# DMIC_DSP register map
Vendor: Texas Instruments
Peripheral module from a debugger description file (folder omap4460).
Registers are 32-bit, read-only, reset 0x0 unless marked. A register's access mark holds for its fields unless they carry their own. Offsets are as the file gives them; lines under a group give offsets from that group; [hi:lo] are bit positions; {n}, {i} and the like mark numbered series; 'fields as' and 'values as' point back to an identical list; <NAME> marks a mode.

## DMIC_DSP
0x00 DMIC_REVISION reset not defined — IP Revision Identifier (X.Y.R) used by software to track features, bugs, and compatibility
  [31:0] REVISION — IP revision
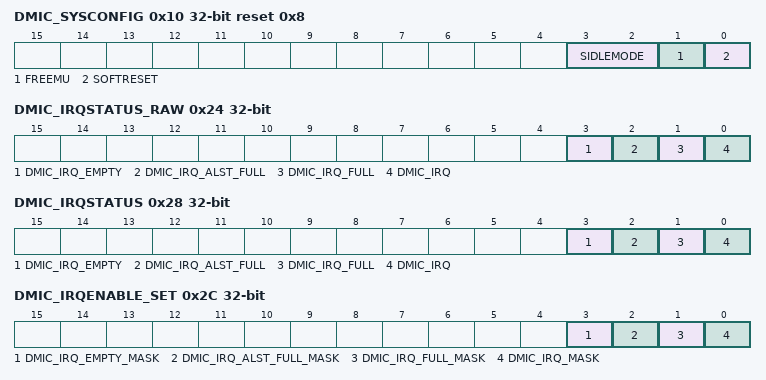
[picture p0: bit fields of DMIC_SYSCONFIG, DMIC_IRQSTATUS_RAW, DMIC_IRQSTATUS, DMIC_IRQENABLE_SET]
0x10 DMIC_SYSCONFIG access per field reset 0x8 — This register allows controlling various parameters of the DMIC interface.
  [3:2] SIDLEMODE rw — Configuration of the local target state management (idlereq/idleack control)
    0=Force-idle. IDLE request is acknowledged unconditionally and immediately.; 1=No-idle. IDLE request is never acknowledged.; 2=Smart-idle. The acknowledgment to an IDLE request is given based on the internal activity.; 3=Smart-idle wakeup capable mode
  [1] FREEMU rw — Sensitivity to emulation (debug) suspend input signal
    0=IP module is sensitive to emulation suspend; 1=IP module is not sensitive to emulation suspend
  [0] SOFTRESET rw — Module software reset. The bit is automatically reset by the hardware. It has same effect as the main hardware reset.
    0=SOFTRESET_0_w (No action); 0=SOFTRESET_0_r (Reset done, no pending action); 1=SOFTRESET_1_r (Reset (software or other) ongoing); 1=SOFTRESET_1_w (Initiate software reset.)
0x24 DMIC_IRQSTATUS_RAW access not given — Component (that is, main) interrupt request status. Check the corresponding secondary status register. Raw status is set even if event is not enabled. Write 1 to set the (raw) status, mostly for debug.
  [3] DMIC_IRQ_EMPTY rw
    0=DMIC_IRQ_EMPTY_0_r (No event pending); 0=DMIC_IRQ_EMPTY_0_w (No action); 1=DMIC_IRQ_EMPTY_1_w (Set); 1=DMIC_IRQ_EMPTY_1_r (IRQ event pending)
  [2] DMIC_IRQ_ALST_FULL — (access RW W1toSet)
    0=DMIC_IRQ_ALST_FULL_0_r (No event pending); 0=DMIC_IRQ_ALST_FULL_0_w (No action); 1=DMIC_IRQ_ALST_FULL_1_w (Set); 1=DMIC_IRQ_ALST_FULL_1_r (IRQ event pending)
  [1] DMIC_IRQ_FULL — (access RW W1toSet)
    0=DMIC_IRQ_FULL_0_r (No event pending); 0=DMIC_IRQ_FULL_0_w (No action); 1=DMIC_IRQ_FULL_1_w (Set); 1=DMIC_IRQ_FULL_1_r (IRQ event pending)
  [0] DMIC_IRQ — (access RW W1toSet)
    0=DMIC_IRQ_0_r (No event pending); 0=DMIC_IRQ_0_w (No action); 1=DMIC_IRQ_1_w (Set); 1=DMIC_IRQ_1_r (IRQ event pending)
0x28 DMIC_IRQSTATUS access not given — Component (that is, main) interrupt request status. Check the corresponding secondary status register. Enabled status is not set unless event is enabled. Write 1 to clear the status after interrupt has been serviced (raw status gets cleared, that is, even if not enabled).
  [3] DMIC_IRQ_EMPTY rw
    0=DMIC_IRQ_EMPTY_0_r (No event pending); 0=DMIC_IRQ_EMPTY_0_w (No action); 1=DMIC_IRQ_EMPTY_1_w (Clear pending event, if any); 1=DMIC_IRQ_EMPTY_1_r (IRQ event pending)
  [2] DMIC_IRQ_ALST_FULL — This interrupt status is set when only one FIFO space is still available. (access RW W1toClr)
    0=DMIC_IRQ_ALST_FULL_0_r (No event pending); 0=DMIC_IRQ_ALST_FULL_0_w (No action); 1=DMIC_IRQ_ALST_FULL_1_w (Clear pending event, if any); 1=DMIC_IRQ_ALST_FULL_1_r (IRQ event pending)
  [1] DMIC_IRQ_FULL — This interrupt status is set when FIFO is full and a new write access has been performed by filter. (access RW W1toClr)
    0=DMIC_IRQ_FULL_0_r (No event pending); 0=DMIC_IRQ_FULL_0_w (No action); 1=DMIC_IRQ_FULL_1_w (Clear pending event, if any.); 1=DMIC_IRQ_FULL_1_r (IRQ event pending)
  [0] DMIC_IRQ — This interrupt status is set when FIFO threshold value defined inDMIC_FIFO_CTRL is reached. (access RW W1toClr)
    0=DMIC_IRQ_0_r (No event pending); 0=DMIC_IRQ_0_w (No action); 1=DMIC_IRQ_1_w (Clear pending event, if any.); 1=DMIC_IRQ_1_r (IRQ event pending)
0x2C DMIC_IRQENABLE_SET access not given — Component (that is, main) interrupt request enable. Write 1 to set (enable interrupt). Readout equal to corresponding _SET register. _SET register is cleared when writing 1 to _CLR register.
  [3] DMIC_IRQ_EMPTY_MASK — (access RW W1toSet)
    0=DMIC_IRQ_EMPTY_MASK_0_r (Interrupt disabled); 0=DMIC_IRQ_EMPTY_MASK_0_w (No action); 1=DMIC_IRQ_EMPTY_MASK_1_w (Enable interrupt); 1=DMIC_IRQ_EMPTY_MASK_1_r
  [2] DMIC_IRQ_ALST_FULL_MASK — (access RW W1toSet)
    0=DMIC_IRQ_ALST_FULL_MASK_0_r (Interrupt disabled); 0=DMIC_IRQ_ALST_FULL_MASK_0_w (No action); 1=DMIC_IRQ_ALST_FULL_MASK_1_w (Enable interrupt); 1=DMIC_IRQ_ALST_FULL_MASK_1_r (Interrupt enabled)
  [1] DMIC_IRQ_FULL_MASK — (access RW W1toSet)
    0=DMIC_IRQ_FULL_MASK_0_r (Interrupt disabled); 0=DMIC_IRQ_FULL_MASK_0_w (No action); 1=DMIC_IRQ_FULL_MASK_1_w (Enable interrupt); 1=DMIC_IRQ_FULL_MASK_1_r (Interrupt enabled)
  [0] DMIC_IRQ_MASK — (access RW W1toSet)
    0=DMIC_IRQ_MASK_0_r (Interrupt disabled); 0=DMIC_IRQ_MASK_0_w (No action); 1=DMIC_IRQ_MASK_1_w (Enable interrupt); 1=DMIC_IRQ_MASK_1_r (Interrupt enabled)
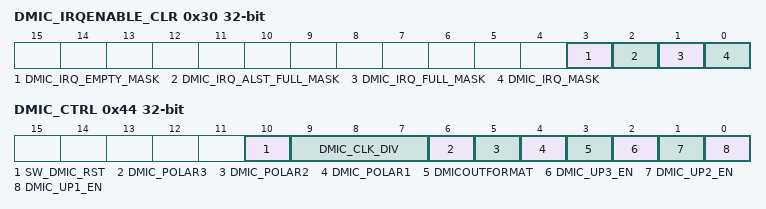
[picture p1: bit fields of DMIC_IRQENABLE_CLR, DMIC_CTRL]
0x30 DMIC_IRQENABLE_CLR access not given — Component (that is, main) interrupt request enable Write 1 to clear (disable interrupt). Readout equal to corresponding _SET register. _SET register is cleared when writing 1 to _CLR register.
  [3] DMIC_IRQ_EMPTY_MASK — (access RW W1toClr)
    0=DMIC_IRQ_EMPTY_MASK_0_r (Interrupt disabled); 0=DMIC_IRQ_EMPTY_MASK_0_w (No action); 1=DMIC_IRQ_EMPTY_MASK_1_w (Disable interrupt); 1=DMIC_IRQ_EMPTY_MASK_1_r (Interrupt enabled)
  [2] DMIC_IRQ_ALST_FULL_MASK — (access RW W1toClr)
    0=DMIC_IRQ_ALST_FULL_MASK_0_r (Interrupt disabled); 0=DMIC_IRQ_ALST_FULL_MASK_0_w (No action); 1=DMIC_IRQ_ALST_FULL_MASK_1_w (Disable interrupt); 1=DMIC_IRQ_ALST_FULL_MASK_1_r (Interrupt enabled)
  [1] DMIC_IRQ_FULL_MASK — (access RW W1toClr)
    0=DMIC_IRQ_FULL_MASK_0_r (Interrupt disabled); 0=DMIC_IRQ_FULL_MASK_0_w (No action); 1=DMIC_IRQ_FULL_MASK_1_w (Disable interrupt); 1=DMIC_IRQ_FULL_MASK_1_r (Interrupt enabled)
  [0] DMIC_IRQ_MASK — (access RW W1toClr)
    0=DMIC_IRQ_MASK_0_r (Interrupt disabled); 0=DMIC_IRQ_MASK_0_w (No action); 1=DMIC_IRQ_MASK_1_w (Disable interrupt); 1=DMIC_IRQ_MASK_1_r (Interrupt enabled)
0x34 DMIC_IRQWAKEEN access per field reset 0x1 — This register allows to enable the wake-up capability on interrupt event.
  [0] IRQ_WAKEUP_EN rw — Write 1 to allow wake-up by IRQ source (register threshold value reached).
0x38 DMIC_DMAENABLE_SET access not given — Component DMA enable (1 bit per DMA-capable channel)/Write 1 to set (enable DMA). Readout equal to corresponding _SET register. _SET register is cleared when writing 1 to _CLR register.
  [0] DMA_ENABLE — Write 1 to set (enable DMA request) (access RW W1toSet)
    0=DMA_ENABLE_0_r (Interrupt disabled); 0=DMA_ENABLE_0_w (No action); 1=DMA_ENABLE_1_w (Enable interrupt); 1=DMA_ENABLE_1_r (Interrupt enabled)
0x3C DMIC_DMAENABLE_CLR access not given — Component DMA enable (1 bit per DMA-capable channel)/Write 1 to clear (disable DMA). Readout equal to corresponding _SET register. _SET register is cleared when writing 1 to _CLR register.
  [0] DMA_ENABLE — Write 1 to clear (disable DMA request) (access RW W1toClr)
    0=DMA_ENABLE_0_r (Interrupt disabled); 0=DMA_ENABLE_0_w (No action); 1=DMA_ENABLE_1_w (Disable interrupt); 1=DMA_ENABLE_1_r (Interrupt enabled)
0x40 DMIC_DMAWAKEEN access per field reset 0x1 — This register allows to enable the wake-up capability on DMA request event.
  [0] DMA_WAKEUP_EN rw — Write 1 to allow wakeup by DMA source (register threshold value reached).
0x44 DMIC_CTRL access per field — This register configures the various parameters of the DMIC module.
  [10] SW_DMIC_RST rw — Software reset of the DMIC path. When 1, the DMIC path is reset. Clearing the reset is done by writing 0 to the register.
  [9:7] DMIC_CLK_DIV rw — Select the DMIC output clock frequency. See for details.
  [6] DMIC_POLAR3 rw
    0=When 0, the left data is generated in the external microphone 3 on abe_dmic_clk3 low level; 1=When 1, the left data is generated in the external microphone 3 on abe_dmic_clk3 high level
  [5] DMIC_POLAR2 rw
    0=When 0, the left data is generated in the external microphone 2 on abe_dmic_clk2 low level; 1=When 1, the left data is generated in the external microphone 2 on abe_dmic_clk2 high level
  [4] DMIC_POLAR1 rw
    0=When 0, the left data is generated in the external microphone 1 on abe_dmic_clk1 low level; 1=When 1, the left data is generated in the external microphone 1 on abe_dmic_clk1 high level
  [3] DMICOUTFORMAT rw — When 0, the data going out from the FIFO are left shifted from 8 bits. When 1, the data going are signed extended on 32 bits
  [2] DMIC_UP3_EN rw — When 1, uplink path 3 is powered up.
  [1] DMIC_UP2_EN rw — When 1, uplink path 2 is powered up.
  [0] DMIC_UP1_EN rw — When 1, uplink path 1 is powered up.
0x48 DMIC_DATA_REG — DMIC FIFO data
  [31:0] DMIC_DATA
0x4C DMIC_FIFO_CTRL access per field reset 0x2 — This register sets the FIFO threshold for the data-ready event.
  [3:0] DMIC_TRESH rw — Uplink FIFO threshold
0x50 DMIC_FIFO_DMIC1R_DATA — Data of the first FIFO DMIC right channel
  [23:0] FIFO_DMIC1R_DAT — Data of the right FIFO DMIC path 1
0x54 DMIC_FIFO_DMIC1L_DATA — Data of the first FIFO DMIC left channel
  [23:0] FIFO_DMIC1R_DAT — Data of the left FIFO DMIC path 1
0x58 DMIC_FIFO_DMIC2R_DATA — Data of the second FIFO DMIC right channel
  [23:0] FIFO_DMIC2R_DAT — Data of the right FIFO DMIC path 2
0x5C DMIC_FIFO_DMIC2L_DATA — Data of the second FIFO DMIC left channel
  [23:0] FIFO_DMIC2L_DAT — Data of the left FIFO DMIC path 2
0x60 DMIC_FIFO_DMIC3R_DATA — Data of the third FIFO DMIC right channel
  [23:0] FIFO_DMIC3R_DAT — Data of the right FIFO DMIC path 3
0x64 DMIC_FIFO_DMIC3L_DATA — Data of the third FIFO DMIC left channel
  [23:0] FIFO_DMIC3R_DAT — Data of the left FIFO DMIC path 3
